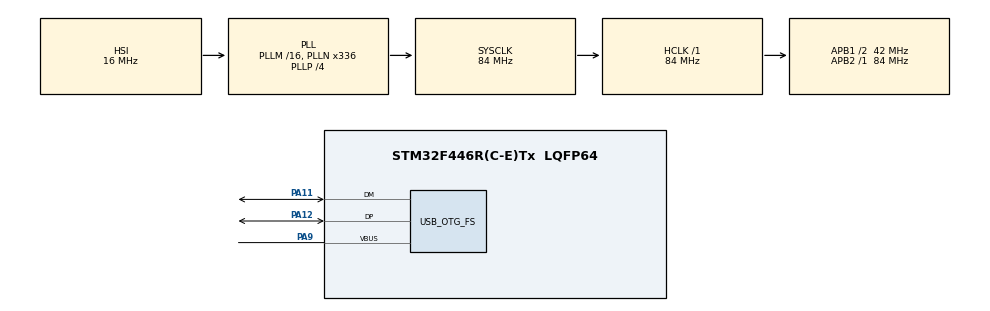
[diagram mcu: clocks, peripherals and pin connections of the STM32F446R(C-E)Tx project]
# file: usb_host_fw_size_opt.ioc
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FATFS._USE_FIND=1
Mcu.Family=STM32F4
Mcu.Name=STM32F446R(C-E)Tx
Mcu.Package=LQFP64
NVIC.OTG_FS_IRQn=true\:0\:0\:false\:false\:true\:false\:true\:true
NVIC.PriorityGroup=NVIC_PRIORITYGROUP_4
PA11.Mode=Host_Only
PA11.Signal=USB_OTG_FS_DM
PA12.Mode=Host_Only
PA12.Signal=USB_OTG_FS_DP
PA13.Mode=Serial_Wire
PA13.Signal=SYS_JTMS-SWDIO
PA14.Mode=Serial_Wire
PA14.Signal=SYS_JTCK-SWCLK
PA9.Mode=Activate_VBUS
PA9.Signal=USB_OTG_FS_VBUS
ProjectManager.HeapSize=0x200
ProjectManager.StackSize=0x400
ProjectManager.TargetToolchain=STM32CubeIDE
RCC.AHBFreq_Value=84000000
RCC.APB1CLKDivider=RCC_HCLK_DIV2
RCC.APB1Freq_Value=42000000
RCC.APB1TimFreq_Value=84000000
RCC.APB2Freq_Value=84000000
RCC.APB2TimFreq_Value=84000000
RCC.CortexFreq_Value=84000000
RCC.HCLKFreq_Value=84000000
RCC.PLLN=336
RCC.PLLP=RCC_PLLP_DIV4
RCC.PLLQ=7
RCC.PLLSourceVirtualString=RCC_PLLSOURCE_HSI
RCC.SYSCLKFreq_VALUE=84000000
RCC.SYSCLKSource=RCC_SYSCLKSOURCE_PLLCLK
RCC.USBFreq_Value=48000000
RCC.VCOOutputFreq_Value=336000000
USB_HOST.SW_VBUS_DRIVE_MSC_FS=true
USB_HOST.USBH_HandleTypeDef-MSC_FS=hUsbHostFS
USB_HOST.VirtualModeFS=Msc
USB_OTG_FS.VirtualMode=Host_Only
USB_OTG_FS.phy_itface=HCD_PHY_EMBEDDED
VP_FATFS_VS_USB.Mode=USB
VP_USB_HOST_VS_USB_HOST_MSC_FS.Mode=MSC_FS
board=custom

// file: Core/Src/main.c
/* USER CODE BEGIN Header */
/**
  ******************************************************************************
  * @file           : main.c
  * @brief          : Main program body
  ******************************************************************************
  * @attention
  *
  * Copyright (c) 2026 STMicroelectronics.
  * All rights reserved.
  *
  * This software is licensed under terms that can be found in the LICENSE file
  * in the root directory of this software component.
  * If no LICENSE file comes with this software, it is provided AS-IS.
  *
  ******************************************************************************
  */
/* USER CODE END Header */
#include "main.h"
#include "usb_host.h"
#include "usbh_msc.h"

/* USER CODE BEGIN Includes */
extern ApplicationTypeDef Appli_state;
extern USBH_HandleTypeDef hUsbHostFS;
#define APP_ADDR 0x08010000
uint8_t flashed = 0;
/* USER CODE END Includes */

/* USER CODE BEGIN PD */
void JumpToApp(void)
{
    uint32_t sp = *(uint32_t*)APP_ADDR;
    uint32_t resetHandlerAddr = *(uint32_t*)(APP_ADDR + 4);
    void (*resetHandler)(void) = (void*)resetHandlerAddr;

    HAL_Delay(100);

    HAL_DeInit();
    __disable_irq();

    for (int i = 0; i < 8; i++)
    {
        NVIC->ICER[i] = 0xFFFFFFFF;
        NVIC->ICPR[i] = 0xFFFFFFFF;
    }

    SCB->VTOR = APP_ADDR;
    __set_MSP(sp);

    resetHandler();
}

/* ================= FLASH FROM USB ================= */
void Flash_From_USB(void)
{
    uint8_t buffer[512];   // sector size
    uint32_t addr = APP_ADDR;
    uint32_t sector = 0;

    HAL_FLASH_Unlock();

    FLASH_EraseInitTypeDef erase;
    uint32_t error;

    erase.TypeErase = FLASH_TYPEERASE_SECTORS;
    erase.VoltageRange = FLASH_VOLTAGE_RANGE_3;
    erase.Sector = FLASH_SECTOR_4;
    erase.NbSectors = 4;

    if (HAL_FLASHEx_Erase(&erase, &error) != HAL_OK)
    {
        HAL_FLASH_Lock();
        return;
    }

    while (1)
    {
        if (USBH_MSC_Read(&hUsbHostFS, 0, sector, buffer, 1) != USBH_OK)
            break;

        /* simple stop condition */
        if (buffer[0] == 0xFF && buffer[1] == 0xFF)
            break;

        for (int i = 0; i < 512; i += 4)
        {
            uint32_t data = *(uint32_t*)&buffer[i];

            if (HAL_FLASH_Program(FLASH_TYPEPROGRAM_WORD, addr, data) != HAL_OK)
            {
                HAL_FLASH_Lock();
                return;
            }

            addr += 4;
        }

        sector++;
    }

    HAL_FLASH_Lock();

    JumpToApp();
}

/* USER CODE END PD */

void SystemClock_Config(void);
static void MX_GPIO_Init(void);
void MX_USB_HOST_Process(void);

int main(void)
{

  /* MCU Configuration--------------------------------------------------------*/

  /* Reset of all peripherals, Initializes the Flash interface and the Systick. */
  HAL_Init();

  /* Configure the system clock */
  SystemClock_Config();

  /* Initialize all configured peripherals */
  MX_GPIO_Init();
//  MX_FATFS_Init();
  MX_USB_HOST_Init();

  /* Infinite loop */
  while (1)
  {
    MX_USB_HOST_Process();

    /* USER CODE BEGIN 3 */

    if (Appli_state == APPLICATION_READY && flashed == 0)
    {

        HAL_Delay(1000); // stabilize

        Flash_From_USB();

        flashed = 1;
    }
  }
  /* USER CODE END 3 */
}

void SystemClock_Config(void)
{
  RCC_OscInitTypeDef RCC_OscInitStruct = {0};
  RCC_ClkInitTypeDef RCC_ClkInitStruct = {0};

  /** Configure the main internal regulator output voltage
  */
  __HAL_RCC_PWR_CLK_ENABLE();
  __HAL_PWR_VOLTAGESCALING_CONFIG(PWR_REGULATOR_VOLTAGE_SCALE3);

  /** Initializes the RCC Oscillators according to the specified parameters
  * in the RCC_OscInitTypeDef structure.
  */
  RCC_OscInitStruct.OscillatorType = RCC_OSCILLATORTYPE_HSI;
  RCC_OscInitStruct.HSIState = RCC_HSI_ON;
  RCC_OscInitStruct.HSICalibrationValue = RCC_HSICALIBRATION_DEFAULT;
  RCC_OscInitStruct.PLL.PLLState = RCC_PLL_ON;
  RCC_OscInitStruct.PLL.PLLSource = RCC_PLLSOURCE_HSI;
  RCC_OscInitStruct.PLL.PLLM = 16;
  RCC_OscInitStruct.PLL.PLLN = 336;
  RCC_OscInitStruct.PLL.PLLP = RCC_PLLP_DIV4;
  RCC_OscInitStruct.PLL.PLLQ = 7;
  RCC_OscInitStruct.PLL.PLLR = 2;
  if (HAL_RCC_OscConfig(&RCC_OscInitStruct) != HAL_OK)
  {
    Error_Handler();
  }

  /** Initializes the CPU, AHB and APB buses clocks
  */
  RCC_ClkInitStruct.ClockType = RCC_CLOCKTYPE_HCLK|RCC_CLOCKTYPE_SYSCLK
                              |RCC_CLOCKTYPE_PCLK1|RCC_CLOCKTYPE_PCLK2;
  RCC_ClkInitStruct.SYSCLKSource = RCC_SYSCLKSOURCE_PLLCLK;
  RCC_ClkInitStruct.AHBCLKDivider = RCC_SYSCLK_DIV1;
  RCC_ClkInitStruct.APB1CLKDivider = RCC_HCLK_DIV2;
  RCC_ClkInitStruct.APB2CLKDivider = RCC_HCLK_DIV1;

  if (HAL_RCC_ClockConfig(&RCC_ClkInitStruct, FLASH_LATENCY_2) != HAL_OK)
  {
    Error_Handler();
  }
}

static void MX_GPIO_Init(void)
{

  /* GPIO Ports Clock Enable */
  __HAL_RCC_GPIOA_CLK_ENABLE();

}

void Error_Handler(void)
{
  __disable_irq();
  while (1)
  {
  }
}
